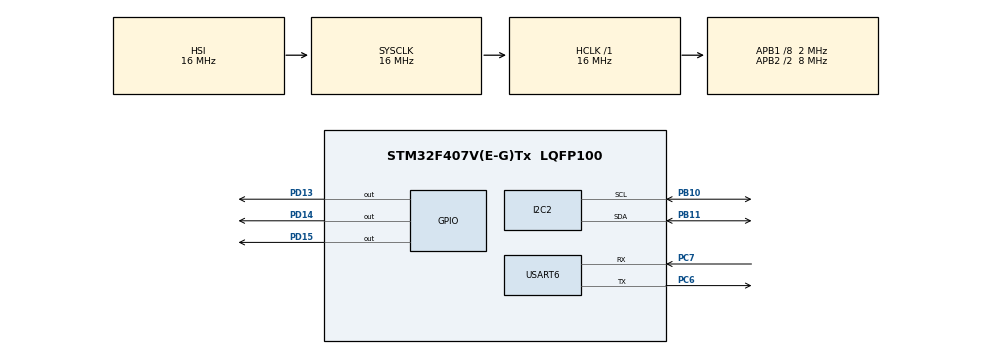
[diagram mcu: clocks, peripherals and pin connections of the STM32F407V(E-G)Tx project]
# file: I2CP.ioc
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Mcu.Family=STM32F4
Mcu.Name=STM32F407V(E-G)Tx
Mcu.Package=LQFP100
NVIC.PriorityGroup=NVIC_PRIORITYGROUP_0
PA13.Mode=Serial_Wire
PA13.Signal=SYS_JTMS-SWDIO
PA14.Mode=Serial_Wire
PA14.Signal=SYS_JTCK-SWCLK
PB10.GPIO_Mode=GPIO_MODE_AF_OD
PB10.GPIO_Pu=GPIO_PULLUP
PB10.Mode=I2C
PB10.Signal=I2C2_SCL
PB11.GPIO_Pu=GPIO_PULLUP
PB11.Mode=I2C
PB11.Signal=I2C2_SDA
PC6.Mode=Asynchronous
PC6.Signal=USART6_TX
PC7.Mode=Asynchronous
PC7.Signal=USART6_RX
PD13.Signal=GPIO_Output
PD14.Signal=GPIO_Output
PD15.Signal=GPIO_Output
ProjectManager.HeapSize=0x200
ProjectManager.StackSize=0x400
ProjectManager.TargetToolchain=MDK-ARM V5.27
RCC.48MHZClocksFreq_Value=14285714.285714285
RCC.AHBFreq_Value=16000000
RCC.APB1CLKDivider=RCC_HCLK_DIV8
RCC.APB1Freq_Value=2000000
RCC.APB1TimFreq_Value=4000000
RCC.APB2CLKDivider=RCC_HCLK_DIV2
RCC.APB2Freq_Value=8000000
RCC.APB2TimFreq_Value=16000000
RCC.CortexFreq_Value=16000000
RCC.HCLKFreq_Value=16000000
RCC.HSE_VALUE=8000000
RCC.HSI_VALUE=16000000
RCC.PLLM=8
RCC.PLLN=50
RCC.PLLP=RCC_PLLP_DIV4
RCC.PLLQ=7
RCC.SYSCLKFreq_VALUE=16000000
RCC.VCOOutputFreq_Value=100000000
USART6.VirtualMode=VM_ASYNC
board=STM32F407G-DISC1

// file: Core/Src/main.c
/* USER CODE BEGIN Header */
/**
  ******************************************************************************
  * @file           : main.c
  * @brief          : Main program body
  ******************************************************************************
  * @attention
  *
  * Copyright (c) 2022 STMicroelectronics.
  * All rights reserved.
  *
  * This software is licensed under terms that can be found in the LICENSE file
  * in the root directory of this software component.
  * If no LICENSE file comes with this software, it is provided AS-IS.
  *
  ******************************************************************************
  */
/* USER CODE END Header */
#include "main.h"
#include<stdio.h>

 I2C_HandleTypeDef hi2c2;

UART_HandleTypeDef huart6;

/* USER CODE BEGIN PV */
char data[2];
	uint8_t buf[2];
	char buff[50],Buf[50];
	uint16_t d,i2c_status;
	uint16_t temp,humidity;
/* USER CODE END PV */

void SystemClock_Config(void);
static void MX_GPIO_Init(void);
static void MX_I2C2_Init(void);
static void MX_USART6_UART_Init(void);

int main(void)
{

  /* MCU Configuration--------------------------------------------------------*/

  /* Reset of all peripherals, Initializes the Flash interface and the Systick. */
  HAL_Init();

  /* Configure the system clock */
  SystemClock_Config();

  /* Initialize all configured peripherals */
  MX_GPIO_Init();
  MX_I2C2_Init();
  MX_USART6_UART_Init();
  /* USER CODE BEGIN 2 */
	if(HAL_I2C_IsDeviceReady(&hi2c2,0x80,5,100)==HAL_OK)
	{
		for (int i=0;i<3;i++)
		{
		HAL_GPIO_TogglePin(GPIOD,GPIO_PIN_14);
		HAL_Delay(1000);
		}
  /* USER CODE END 2 */

  /* Infinite loop */
  while (1)
  {
	HAL_I2C_Master_Transmit(&hi2c2,0x80,&buf[1],1,1000);
		HAL_Delay(100);
		HAL_I2C_Master_Receive(&hi2c2,0x80,(uint8_t *)data,1,1000);
		d=(data[0]<<8)+data[1];
		temp =(-46.85+(0.0026*d));

		buf[1]=0xF5; // Trigger RH measurment   (no hold master)
    HAL_I2C_Master_Transmit(&hi2c2,0x80,&buf[1],1,1000);
    HAL_Delay(100);
	  HAL_I2C_Master_Receive(&hi2c2,0x80,(uint8_t*)data,2,100);
    d=(data[0]<<8) + data[1];
		humidity= -6+(0.0019*d);
		HAL_GPIO_TogglePin(GPIOD,GPIO_PIN_13);
		HAL_Delay(100);

				HAL_UART_Transmit(&huart6,(uint8_t *)buff,sprintf(buff,"Temp = %d\r\n",temp),1000);
	HAL_UART_Transmit(&huart6,(uint8_t *)Buf,sprintf(Buf,"RH = %d\r\n",humidity),1000);
		HAL_Delay(500);
  }
}
}
void SystemClock_Config(void)
{
  RCC_OscInitTypeDef RCC_OscInitStruct = {0};
  RCC_ClkInitTypeDef RCC_ClkInitStruct = {0};

  /** Configure the main internal regulator output voltage
  */
  __HAL_RCC_PWR_CLK_ENABLE();
  __HAL_PWR_VOLTAGESCALING_CONFIG(PWR_REGULATOR_VOLTAGE_SCALE1);

  /** Initializes the RCC Oscillators according to the specified parameters
  * in the RCC_OscInitTypeDef structure.
  */
  RCC_OscInitStruct.OscillatorType = RCC_OSCILLATORTYPE_HSI;
  RCC_OscInitStruct.HSIState = RCC_HSI_ON;
  RCC_OscInitStruct.HSICalibrationValue = RCC_HSICALIBRATION_DEFAULT;
  RCC_OscInitStruct.PLL.PLLState = RCC_PLL_NONE;
  if (HAL_RCC_OscConfig(&RCC_OscInitStruct) != HAL_OK)
  {
    Error_Handler();
  }

  /** Initializes the CPU, AHB and APB buses clocks
  */
  RCC_ClkInitStruct.ClockType = RCC_CLOCKTYPE_HCLK|RCC_CLOCKTYPE_SYSCLK
                              |RCC_CLOCKTYPE_PCLK1|RCC_CLOCKTYPE_PCLK2;
  RCC_ClkInitStruct.SYSCLKSource = RCC_SYSCLKSOURCE_HSI;
  RCC_ClkInitStruct.AHBCLKDivider = RCC_SYSCLK_DIV1;
  RCC_ClkInitStruct.APB1CLKDivider = RCC_HCLK_DIV8;
  RCC_ClkInitStruct.APB2CLKDivider = RCC_HCLK_DIV2;

  if (HAL_RCC_ClockConfig(&RCC_ClkInitStruct, FLASH_LATENCY_0) != HAL_OK)
  {
    Error_Handler();
  }
}

static void MX_I2C2_Init(void)
{

  hi2c2.Instance = I2C2;
  hi2c2.Init.ClockSpeed = 100000;
  hi2c2.Init.DutyCycle = I2C_DUTYCYCLE_2;
  hi2c2.Init.OwnAddress1 = 0;
  hi2c2.Init.AddressingMode = I2C_ADDRESSINGMODE_7BIT;
  hi2c2.Init.DualAddressMode = I2C_DUALADDRESS_DISABLE;
  hi2c2.Init.OwnAddress2 = 0;
  hi2c2.Init.GeneralCallMode = I2C_GENERALCALL_DISABLE;
  hi2c2.Init.NoStretchMode = I2C_NOSTRETCH_DISABLE;
  if (HAL_I2C_Init(&hi2c2) != HAL_OK)
  {
    Error_Handler();
  }

}

static void MX_USART6_UART_Init(void)
{

  huart6.Instance = USART6;
  huart6.Init.BaudRate = 115200;
  huart6.Init.WordLength = UART_WORDLENGTH_8B;
  huart6.Init.StopBits = UART_STOPBITS_1;
  huart6.Init.Parity = UART_PARITY_NONE;
  huart6.Init.Mode = UART_MODE_TX_RX;
  huart6.Init.HwFlowCtl = UART_HWCONTROL_NONE;
  huart6.Init.OverSampling = UART_OVERSAMPLING_16;
  if (HAL_UART_Init(&huart6) != HAL_OK)
  {
    Error_Handler();
  }

}

static void MX_GPIO_Init(void)
{
  GPIO_InitTypeDef GPIO_InitStruct = {0};

  /* GPIO Ports Clock Enable */
  __HAL_RCC_GPIOB_CLK_ENABLE();
  __HAL_RCC_GPIOD_CLK_ENABLE();
  __HAL_RCC_GPIOC_CLK_ENABLE();
  __HAL_RCC_GPIOA_CLK_ENABLE();

  /*Configure GPIO pin Output Level */
  HAL_GPIO_WritePin(GPIOD, GPIO_PIN_13|GPIO_PIN_14|GPIO_PIN_15, GPIO_PIN_RESET);

  /*Configure GPIO pins : PD13 PD14 PD15 */
  GPIO_InitStruct.Pin = GPIO_PIN_13|GPIO_PIN_14|GPIO_PIN_15;
  GPIO_InitStruct.Mode = GPIO_MODE_OUTPUT_PP;
  GPIO_InitStruct.Pull = GPIO_NOPULL;
  GPIO_InitStruct.Speed = GPIO_SPEED_FREQ_LOW;
  HAL_GPIO_Init(GPIOD, &GPIO_InitStruct);

}

void Error_Handler(void)
{
  __disable_irq();
  while (1)
  {
  }
}
